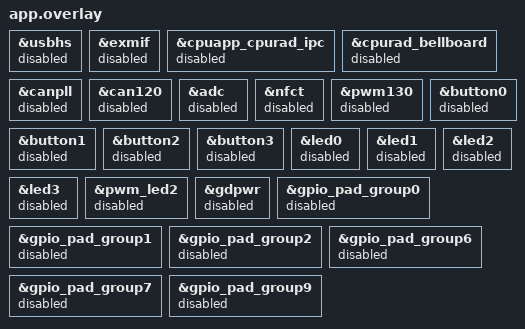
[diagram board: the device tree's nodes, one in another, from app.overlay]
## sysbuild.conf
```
SB_CONFIG_NRF_HALTIUM_GENERATE_UICR=n
```

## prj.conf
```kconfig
CONFIG_NRFS=n
CONFIG_PM=n
CONFIG_POWER_DOMAIN=n
CONFIG_CLOCK_CONTROL=n
CONFIG_XIP=n
CONFIG_ARM_MPU=n
CONFIG_DCACHE=n
# CONFIG_SRAM_VECTOR_TABLE=y
# SRAM execution can probably be done in a nicer way
# CONFIG_USE_DT_CODE_PARTITION=y
```

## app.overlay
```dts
&usbhs {
	status = "disabled";
};

&exmif {
	status = "disabled";
};

&cpuapp_cpurad_ipc {
	status = "disabled";
};

&cpurad_bellboard {
	status = "disabled";
};

&canpll {
	status = "disabled";
};

&can120 {
	status = "disabled";
};

&adc {
	status = "disabled";
};

&nfct {
	status = "disabled";
};

&pwm130 {
	status = "disabled";
};

&button0 {
	status = "disabled";
};

&button1 {
	status = "disabled";
};

&button2 {
	status = "disabled";
};

&button3 {
	status = "disabled";
};

&led0 {
	status = "disabled";
};

&led1 {
	status = "disabled";
};

&led2 {
	status = "disabled";
};

&led3 {
	status = "disabled";
};

&pwm_led2 {
	status = "disabled";
};

&gdpwr {
	status = "disabled";
};

&gpio_pad_group0 {
	status = "disabled";
};

&gpio_pad_group1 {
	status = "disabled";
};

&gpio_pad_group2 {
	status = "disabled";
};

&gpio_pad_group6 {
	status = "disabled";
};

&gpio_pad_group7 {
	status = "disabled";
};

&gpio_pad_group9 {
	status = "disabled";
};
```

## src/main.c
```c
/*
 * Copyright (c) 2012-2014 Wind River Systems, Inc.
 *
 * SPDX-License-Identifier: Apache-2.0
 */

#include <hal/nrf_gpio.h>
#include <stdio.h>
#include <zephyr/kernel.h>

static int disable_gpio_retention(void)
{
	NRF_GPIO_Type *gpio_regs[GPIO_COUNT] = GPIO_REG_LIST;

	for (int i = 0; i < NRFX_ARRAY_SIZE(gpio_regs); i++) {
		nrf_gpio_port_retain_set(gpio_regs[i], 0);
	}

	return 0;
}

SYS_INIT(disable_gpio_retention, EARLY, 0);

int main(void)
{
	printf("Hello World! %s\n", CONFIG_BOARD_TARGET);

	return 0;
}
```
